# WS63 register map
File version: 1.0
CPU: other r0p0, little endian, MPU, FPU, 3 interrupt priority bits
Registers are 32-bit, read-write, reset 0x0 unless marked. A register's access mark holds for its fields unless they carry their own. Offsets are from the block's base; [hi:lo] are bit positions; {n}, {i} and the like mark numbered series.

## FAMA_REMAP — SYS_CTL2 sub-block: Flash Address Map Remap - up to 12 regions for boot-time address redirection
Base 0x44007800
0x00 REMAP_SRC_BASE — Remap source base address (address >> 12). Up to 12 regions, offset 0x0 + 0x4*n
0x20 REMAP_LEN — Remap region length (end address >> 12). offset 0x20 + 0x4*n
0x40 REMAP_DST_BASE — Remap destination base offset (dest - src). offset 0x40 + 0x4*n

## WLMAC_STATS — Read-only Wi-Fi MAC receive statistics used by the WS63 mask-ROM hh503_get_mac_rx_statistics_data implementation
Base 0x44210000
0x48 RX_FILTER_CONTROL ro — Read-only diagnostic view of the packed MAC receive-filter control state. The mask-ROM hal_set_rx_filter_reg helper expands its command bits into this register; this alias deliberately exposes no write capability
  [31:0] control — Active packed receive-filter control state
0x400 VAP0_STATION_ADDRESS_TAIL ro — Read-only diagnostic view of station-address bytes 2 through 5 for hardware VAP0
  [31:0] bytes — Station-address bytes 2 through 5 in network byte order
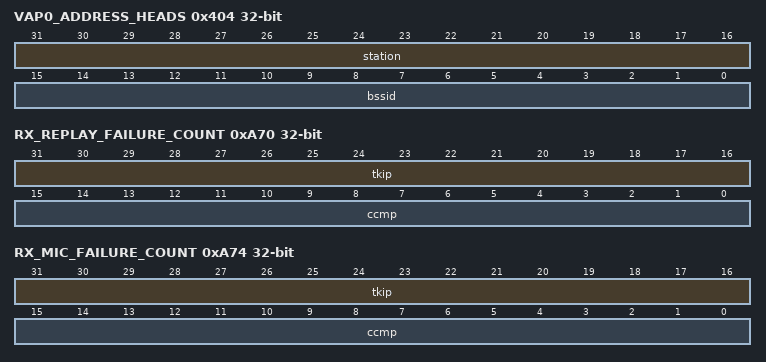
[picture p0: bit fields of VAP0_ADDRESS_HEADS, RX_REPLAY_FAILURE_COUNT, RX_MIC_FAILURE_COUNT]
0x404 VAP0_ADDRESS_HEADS ro — Read-only diagnostic view combining BSSID bytes 0 and 1 in the low halfword and station-address bytes 0 and 1 in the high halfword
  [31:16] station — Station-address bytes 0 and 1 in network byte order
  [15:0] bssid — BSSID bytes 0 and 1 in network byte order
0x408 VAP0_BSSID_TAIL ro — Read-only diagnostic view of BSSID bytes 2 through 5 for hardware VAP0
  [31:0] bytes — BSSID bytes 2 through 5 in network byte order
0xA38 RX_AMPDU_COUNT ro — Received aggregate MPDU count; the mask-ROM helper consumes the low 16 bits
  [15:0] count — Received aggregate MPDU count
0xA48 RX_SUCCESS_MPDU_COUNT ro — Received non-aggregate MPDUs with a valid FCS
  [31:0] count — Successful received MPDU count
0xA4C RX_FAILED_MPDU_COUNT ro — Received non-aggregate MPDUs with an invalid FCS
  [31:0] count — Failed received MPDU count
0xA5C RX_FILTERED_MPDU_COUNT ro — MPDUs rejected by the MAC receive filter; the mask-ROM helper consumes the low 16 bits
  [15:0] count — Filtered received MPDU count
0xA70 RX_REPLAY_FAILURE_COUNT ro — Receive replay failures reported by the MAC statistics helper. The WS63 mask-ROM hh503_get_mac_statistics_data implementation reads this register; TKIP occupies the high halfword and CCMP the low halfword
  [31:16] tkip — TKIP replay failure count
  [15:0] ccmp — CCMP replay failure count
0xA74 RX_MIC_FAILURE_COUNT ro — Receive MIC failures reported by the MAC statistics helper. The WS63 mask-ROM hh503_get_mac_statistics_data implementation reads this register; TKIP occupies the high halfword and CCMP the low halfword
  [31:16] tkip — TKIP MIC failure count
  [15:0] ccmp — CCMP MIC failure count
0xA7C RX_KEY_SEARCH_FAILURE_COUNT ro — Receive key-search failures reported by the WS63 mask-ROM hh503_get_mac_statistics_data implementation
  [15:0] count — Receive key-search failure count
0xB3C RX_SUCCESS_MPDU_IN_AMPDU_COUNT ro — MPDUs with a valid FCS received inside an aggregate
  [31:0] count — Successful MPDUs inside aggregate count
0xB40 RX_FAILED_MPDU_IN_AMPDU_COUNT ro — MPDUs with an invalid FCS received inside an aggregate
  [31:0] count — Failed MPDUs inside aggregate count

## BT_EM_CTL — Bluetooth exchange-memory control used while changing shared RAM ownership
Base 0x49003000
0x74 EM_GT_MODE — Bluetooth exchange-memory gate mode
  [0] enable — Temporarily gate Bluetooth exchange-memory access

## RISCV_PATCH — RISC-V instruction patch controller used to redirect mask-ROM entry points to application-provided fixes
Base 0xE0000000
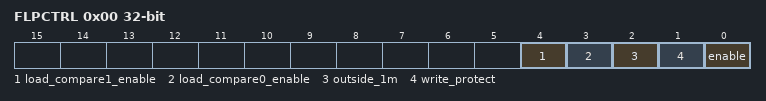
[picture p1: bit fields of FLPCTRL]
0x00 FLPCTRL — Instruction patch controller configuration
  [4] load_compare1_enable — Enable load-address comparison register 1
  [3] load_compare0_enable — Enable load-address comparison register 0
  [2] outside_1m — Select long-jump remap entries whose destinations may be outside the source 1 MiB region
  [1] write_protect — Protect the comparison registers from writes
  [0] enable — Enable instruction patch matching
0x04 FLPRMP — Base address of the instruction remap table
0x08 FLPLACMP0 — Optional load-address comparison register 0
0x0C FLPLACMP1 — Optional load-address comparison register 1
{0x10+4i} FLPIACMP[{i}] (i=0..191) — Instruction-address comparison register {i}; bit 0 enables the entry and bits 31:1 hold the halfword-aligned mask-ROM address
